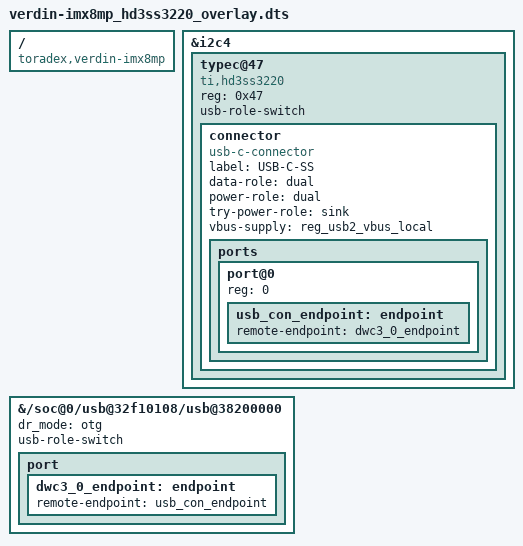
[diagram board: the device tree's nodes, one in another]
/dts-v1/;
/plugin/;

#include <dt-bindings/gpio/gpio.h>
#include <dt-bindings/usb/pd.h>

/ {
    compatible = "toradex,verdin-imx8mp";

    fragment@0 {
        target = <&i2c4>;
        __overlay__ {
            #address-cells = <1>;
            #size-cells = <0>;

            typec@47 {
                compatible = "ti,hd3ss3220";
                reg = <0x47>;
                status = "okay";
                usb-role-switch;

                connector {
                    compatible = "usb-c-connector";
                    label = "USB-C-SS";
                    data-role = "dual";
                    power-role = "dual";
                    try-power-role = "sink";
                    /* Trỏ trực tiếp đến node regulator bằng đường dẫn tuyệt đối */
                    vbus-supply = <&reg_usb2_vbus_local>;

                    ports {
                        #address-cells = <1>;
                        #size-cells = <0>;
                        port@0 {
                            reg = <0>;
                            usb_con_endpoint: endpoint {
                                remote-endpoint = <&dwc3_0_endpoint>;
                            };
                        };
                    };
                };
            };
        };
    };

    fragment@1 {
        target-path = "/soc@0/usb@32f10108/usb@38200000";
        __overlay__ {
            status = "okay";
            dr_mode = "otg";
            usb-role-switch;
            port {
                dwc3_0_endpoint: endpoint {
                    remote-endpoint = <&usb_con_endpoint>;
                };
            };
        };
    };

    /* Định nghĩa symbol nội bộ để trỏ đến regulator hệ thống */
    __symbols__ {
        reg_usb2_vbus_local = "/regulator-usb2-vbus";
    };
};
